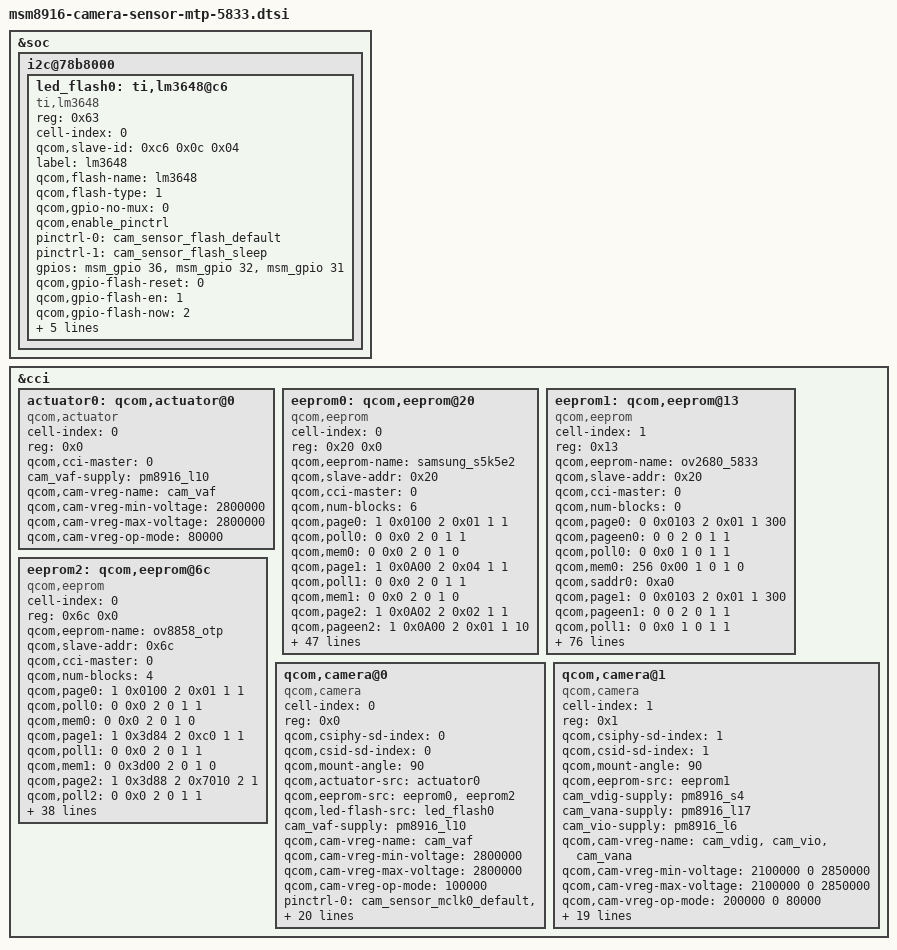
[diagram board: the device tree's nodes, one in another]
/*
 * Copyright (c) 2014-2015, The Linux Foundation. All rights reserved.
 *
 * This program is free software; you can redistribute it and/or modify
 * it under the terms of the GNU General Public License version 2 and
 * only version 2 as published by the Free Software Foundation.
 *
 * This program is distributed in the hope that it will be useful,
 * but WITHOUT ANY WARRANTY; without even the implied warranty of
 * MERCHANTABILITY or FITNESS FOR A PARTICULAR PURPOSE.  See the
 * GNU General Public License for more details.
 */

&soc {
// [5833][FlashLED][akenhsu] Porting LM3648 Flash LED for ASUS 5833 20160324 BEGIN
	i2c@78b8000 { /* BLSP1 QUP4 */
		led_flash0: ti,lm3648@c6 {
			reg = <0x63>;
			cell-index = <0>;
			qcom,slave-id = <0xc6 0x0c 0x04>;
			compatible = "ti,lm3648";
			label = "lm3648";
			qcom,flash-name = "lm3648";
			qcom,flash-type = <1>;
			qcom,gpio-no-mux = <0>;
			qcom,enable_pinctrl;
			pinctrl-names = "cam_flash_default", "cam_flash_suspend";
			pinctrl-0 = <&cam_sensor_flash_default>;
			pinctrl-1 = <&cam_sensor_flash_sleep>;
			gpios = <&msm_gpio 36 0>,
					<&msm_gpio 32 0>,
				<&msm_gpio 31 0>;
			qcom,gpio-flash-reset = <0>;
			qcom,gpio-flash-en = <1>;
			qcom,gpio-flash-now = <2>;
			qcom,gpio-req-tbl-num = <0 1 2>;
			qcom,gpio-req-tbl-flags = <0 0 0>;
			qcom,gpio-req-tbl-label = "FLASH_RST",
				"FLASH_EN",
				"FLASH_NOW";
			qcom,cci-master = <0>;
		};
	};
// [5833][FlashLED]20160324 END
};

&cci {

	actuator0: qcom,actuator@0 {
		cell-index = <0>;
		reg = <0x0>;
		compatible = "qcom,actuator";
		qcom,cci-master = <0>;
		cam_vaf-supply = <&pm8916_l10>;
		qcom,cam-vreg-name = "cam_vaf";
		qcom,cam-vreg-min-voltage = <2800000>;
		qcom,cam-vreg-max-voltage = <2800000>;
		qcom,cam-vreg-op-mode = <80000>;
	};

	eeprom0: qcom,eeprom@20 {
		cell-index = <0>;
		reg = <0x20 0x0>;
		qcom,eeprom-name = "samsung_s5k5e2";
		compatible = "qcom,eeprom";
		qcom,slave-addr = <0x20>; // S5K5E2
		qcom,cci-master = <0>;

		qcom,num-blocks = <6>;
		qcom,page0 = <1 0x0100 2 0x01 1 1>;
		qcom,poll0 = <0 0x0 2 0 1 1>;
		qcom,mem0 = <0 0x0 2 0 1 0>;
		qcom,page1 = <1 0x0A00 2 0x04 1 1>;
		qcom,poll1 = <0 0x0 2 0 1 1>;
		qcom,mem1 = <0 0x0 2 0 1 0>;
		qcom,page2 = <1 0x0A02 2 0x02 1 1>;
		qcom,pageen2 = <1 0x0A00 2 0x01 1 10>;
		qcom,poll2 = <0 0x0 2 0 1 1>;
		qcom,mem2 = <64 0x0A04 2 0 1 0>;
		qcom,page3 = <1 0x0A02 2 0x03 1 1>;
		qcom,pageen3 = <1 0x0A00 2 0x01 1 10>;
		qcom,poll3 = <0 0x0 2 0 1 1>;
		qcom,mem3 = <64 0x0A04 2 0 1 0>; 
		qcom,page4 = <1 0x0A02 2 0x0f 1 1>;
		qcom,pageen4 = <1 0x0A00 2 0x01 1 10>;
		qcom,poll4 = <0 0x0 2 0 1 1>;
		qcom,mem4 = <2 0x0A42 2 0 1 0>; 
		qcom,page5 = <1 0x0A00 2 0x04 1 1>;
		qcom,pageen5 = <1 0x0A00 2 0x00 1 10>;
		qcom,poll5 = <0 0x0 2 0 1 1>;
		qcom,mem5 = <0 0x0 2 0 1 0>;


		pinctrl-names = "cam_default", "cam_suspend";
		pinctrl-0 = <&cam_sensor_mclk0_default &cam_sensor_rear_default>;
		pinctrl-1 = <&cam_sensor_mclk0_sleep &cam_sensor_rear_sleep>;
		qcom,gpio-no-mux = <0>; //no use on the code
		gpios = <&msm_gpio 26 0>,
			<&msm_gpio 34 0>,
			<&msm_gpio 8 0>,
			<&msm_gpio 9 0>,
			<&msm_gpio 23 0>,
			<&msm_gpio 22 0>;
		qcom,gpio-reset = <1>;
		qcom,gpio-vio = <2>;
		qcom,gpio-vana = <3>;
		qcom,gpio-vdig = <4>;
		qcom,gpio-req-tbl-num = <0 1 2 3 4>;
		qcom,gpio-req-tbl-flags = <1 0 0 0 0>;
		qcom,gpio-req-tbl-label = "CAMIF_MCLK",
			"CAM_RESET1",
			"CAM_1V8_EN",
			"CAM_2V8_EN",
			"CAM_1V2_EN";
	
		//qcom,gpio-set-tbl-num = <1 1>;
		//qcom,gpio-set-tbl-flags = <0 2>;
		//qcom,gpio-set-tbl-delay = <1000 4000>;
		qcom,csi-lane-assign = <0x4320>;
		qcom,csi-lane-mask = <0x3>;
		qcom,cam-power-seq-type = "sensor_gpio", "sensor_gpio", "sensor_gpio","sensor_gpio", //init gpio to low
		 "sensor_gpio", "sensor_gpio", "sensor_gpio", "sensor_clk","sensor_gpio";
		qcom,cam-power-seq-val = "sensor_gpio_reset","sensor_gpio_vdig", "sensor_gpio_vana", "sensor_gpio_vio",
			     "sensor_gpio_vio", "sensor_gpio_vana","sensor_gpio_vdig" ,"sensor_cam_mclk","sensor_gpio_reset";
		qcom,cam-power-seq-cfg-val = <0 0 0 0  1 1 1 23880000 1>;
		qcom,cam-power-seq-delay =   <1 1 1 10 5 0 0  10      5>;
		qcom,mclk-23880000;		
		clocks = <&clock_gcc clk_mclk0_clk_src>,
				<&clock_gcc clk_gcc_camss_mclk0_clk>;
		clock-names = "cam_src_clk", "cam_clk";
	};
	eeprom1: qcom,eeprom@13 {
		cell-index = <1>;
		reg = <0x13>;
		qcom,eeprom-name = "ov2680_5833";
		compatible = "qcom,eeprom";
		qcom,slave-addr = <0x20>; // OV2680
		qcom,cci-master = <0>; // Adding
		
		qcom,num-blocks = <0>;

		qcom,page0 = <0 0x0103 2 0x01 1 300>;		
		qcom,pageen0 = <0 0 2 0 1 1>;		
		qcom,poll0 = <0 0x0 1 0 1 1>;
		qcom,mem0 = <256 0x00 1 0 1 0>;
		qcom,saddr0 = <0xa0>;

		qcom,page1 = <0 0x0103 2 0x01 1 300>;		
		qcom,pageen1 = <0 0 2 0 1 1>;
		qcom,poll1 = <0 0x0 1 0 1 1>;
		qcom,mem1 = <256 0x00 1 0 1 0>;
		qcom,saddr1 = <0xa2>;	
		
		qcom,page2 = <0 0x0103 2 0x01 1 300>;			
		qcom,pageen2 = <0 0 2 0 1 1>;
		qcom,poll2 = <0 0x0 1 0 1 1>;
		qcom,mem2 = <256 0x00 1 0 1 0>;
		qcom,saddr2 = <0xa4>;	

		qcom,page3 = <0 0x0103 2 0x01 1 300>;
		qcom,pageen3 = <0 0 2 0 1 1>;
		qcom,poll3 = <0 0x0 1 0 1 1>;
		qcom,mem3 = <256 0x00 1 0 1 0>;
		qcom,saddr3 = <0xa6>;
		
		qcom,page4 = <0 0x0103 2 0x01 1 300>;
		qcom,pageen4 = <0 0 2 0 1 1>;
		qcom,poll4 = <0 0x0 1 0 1 1>;
		qcom,mem4 = <256 0x00 1 0 1 0>;
		qcom,saddr4 = <0xa8>;
		
		qcom,page5 = <0 0x0103 2 0x01 1 300>;
		qcom,pageen5 = <0 0 2 0 1 1>;
		qcom,poll5 = <0 0x0 1 0 1 1>;
		qcom,mem5 = <256 0x00 1 0 1 0>;
		qcom,saddr5 = <0xaa>;
		
		qcom,page6 = <0 0x0103 2 0x01 1 300>;
		qcom,pageen6 = <0 0 2 0 1 1>;
		qcom,poll6 = <0 0x0 1 0 1 1>;
		qcom,mem6 = <256 0x00 1 0 1 0>;
		qcom,saddr6 = <0xac>;	
		
		qcom,page7 = <0 0x0103 2 0x01 1 300>;
		qcom,pageen7 = <0 0 2 0 1 1>;
		qcom,poll7 = <0 0x0 1 0 1 1>;
		qcom,mem7 = <256 0x00 1 0 1 0>;
		qcom,saddr7 = <0xae>;

		cam_vdig-supply = <&pm8916_s4>;
		cam_vio-supply = <&pm8916_l17>;
		cam_vana-supply = <&pm8916_l6>;
		qcom,cam-vreg-name = "cam_vdig", "cam_vio", "cam_vana";
		qcom,cam-vreg-min-voltage = <2100000 0 2850000>;
		qcom,cam-vreg-max-voltage = <2100000 0 2850000>;
		qcom,cam-vreg-op-mode = <200000 0 80000>;
		pinctrl-names = "cam_default", "cam_suspend";
		pinctrl-0 = <&cam_sensor_mclk1_default &cam_sensor_front_default>;
		pinctrl-1 = <&cam_sensor_mclk1_sleep &cam_sensor_front_sleep>;
		qcom,gpio-no-mux = <0>;
		gpios = <&msm_gpio 27 0>,
			<&msm_gpio 33 0>,
			<&msm_gpio 8 0>,
			<&msm_gpio 9 0>,
			<&msm_gpio 23 0>;
		qcom,gpio-reset = <1>;
		qcom,gpio-vio = <2>;
		qcom,gpio-vana = <3>;
		qcom,gpio-vdig = <4>;
		qcom,gpio-req-tbl-num = <0 1 2 3 4>;
		qcom,gpio-req-tbl-flags = <1 0 0 0 0>;
		qcom,gpio-req-tbl-label = "CAMIF_MCLK",
			"CAM_RESET",
			"CAM_1V8_EN",
			"CAM_2V8_EN",
			"CAM_1V2_EN";
		qcom,gpio-set-tbl-num = <1 1>;
		qcom,gpio-set-tbl-flags = <0 2>;
		qcom,gpio-set-tbl-delay = <1000 4000>;

		qcom,cam-power-seq-type = "sensor_gpio", "sensor_gpio", "sensor_gpio",
			"sensor_gpio", "sensor_gpio", "sensor_gpio",
			"sensor_gpio", "sensor_gpio", "sensor_clk", "sensor_gpio";
		qcom,cam-power-seq-val = "sensor_gpio_vio", "sensor_gpio_vana", "sensor_gpio_vdig",
			"sensor_gpio_vio", "sensor_gpio_vana", "sensor_gpio_vdig",
			"sensor_gpio_reset", "sensor_gpio_reset", "sensor_cam_mclk", "sensor_gpio_reset";
		qcom,cam-power-seq-cfg-val = <0 0 0 1 1 1 0 1 23880000 1>;
		qcom,cam-power-seq-delay = <0 0 0 1 1 1 15 10 10 10>;

		qcom,mclk-23880000;
		clocks = <&clock_gcc clk_mclk1_clk_src>,
				<&clock_gcc clk_gcc_camss_mclk1_clk>;
		clock-names = "cam_src_clk", "cam_clk";
	};	
	eeprom2: qcom,eeprom@6c {
		cell-index = <0>;
		reg = <0x6c 0x0>;
		qcom,eeprom-name = "ov8858_otp";
		compatible = "qcom,eeprom";
		qcom,slave-addr = <0x6c>; // OV8858
		qcom,cci-master = <0>;

		qcom,num-blocks = <4>;
		qcom,page0 = <1 0x0100 2 0x01 1 1>;
		qcom,poll0 = <0 0x0 2 0 1 1>;
		qcom,mem0 = <0 0x0 2 0 1 0>;
		qcom,page1 = <1 0x3d84 2 0xc0 1 1>;
		qcom,poll1 = <0 0x0 2 0 1 1>;
		qcom,mem1 = <0 0x3d00 2 0 1 0>;
		qcom,page2 = <1 0x3d88 2 0x7010 2 1>;
		qcom,poll2 = <0 0x0 2 0 1 1>;
		qcom,mem2 = <0 0x3d00 2 0 1 0>;
		qcom,page3 = <1 0x3d8A 2 0x720f 2 1>;
		qcom,pageen3 = <1 0x3d81 2 0x01 1 10>;
		qcom,poll3 = <0 0x0 2 0 1 1>;
		qcom,mem3 = <512 0x7010 2 0 1 1>;
/*
		qcom,num-blocks = <9>;
		qcom,page0 = <1 0x0103 2 0x01 1 300>;		
		qcom,pageen0 = <0 0 2 0 1 1>;		
		qcom,poll0 = <0 0x0 1 0 1 1>;		
		qcom,mem0 = <0 0x0 2 0 1 0>;		
		qcom,page1 = <1 0x0100 2 0x01 1 300>;		
		qcom,pageen1 = <1 0x5002 2 0x0 1 10>;		
		qcom,poll1 = <0 0x0 1 0 1 1>;		
		qcom,mem1 = <0 0x0 2 0 1 0>;		
		qcom,page2 = <1 0x3d84 2 0xc0 1 1>;		
		qcom,pageen2 = <0 0 2 0 1 1>;		
		qcom,poll2 = <0 0x0 1 0 1 1>;		
		qcom,mem2 = <0 0x0 2 0 1 0>;		
		qcom,page3 = <1 0x3d88 2 0x70 1 1>;		
		qcom,pageen3 = <0 0 2 0 1 1>;		
		qcom,poll3 = <0 0x0 1 0 1 1>;		
		qcom,mem3 = <0 0x0 2 0 1 0>;		
		qcom,page4 = <1 0x3d89 2 0x10 1 1>;		
		qcom,pageen4 = <0 0 2 0 1 1>;		
		qcom,poll4= <0 0x0 1 0 1 1>;		
		qcom,mem4 = <0 0x0 2 0 1 0>;		
		qcom,page5 = <1 0x3d8A 2 0x72 1 1>;		
		qcom,pageen5 = <0 0 2 0 1 1>;		
		qcom,poll5 = <0 0x0 1 0 1 1>;		
		qcom,mem5 = <0 0x0 2 0 1 0>;		
		qcom,page6 = <1 0x3d8B 2 0x10 1 1>;		
		qcom,pageen6 = <0 0 2 0 1 1>;		
		qcom,poll6 = <0 0x0 1 0 1 1>;		
		qcom,mem6 = <0 0x0 2 0 1 0>;		
		qcom,page7 = <1 0x3d81 2 0x01 1 100>;		
		qcom,pageen7 = <0 0 2 0 1 1>;		
		qcom,poll7 = <0 0x0 1 0 1 1>;		
		qcom,mem7 = <512 0x7010 2 0 1 0>;		
		qcom,page8 = <1 0x0100 2 0 1 10>;		
		qcom,pageen8 = <1 0x5002 2 8 1 10>;		
		qcom,poll8 = <0 0x0 1 0 1 1>;		
		qcom,mem8 = <0 0 2 0 1 0>;
*/

		pinctrl-names = "cam_default", "cam_suspend";
		pinctrl-0 = <&cam_sensor_mclk0_default &cam_sensor_rear_default>;
		pinctrl-1 = <&cam_sensor_mclk0_sleep &cam_sensor_rear_sleep>;
		qcom,gpio-no-mux = <0>; //no use on the code
		gpios = <&msm_gpio 26 0>,
			<&msm_gpio 34 0>,
			<&msm_gpio 8 0>,
			<&msm_gpio 9 0>,
			<&msm_gpio 23 0>,
			<&msm_gpio 22 0>;
		qcom,gpio-reset = <1>;
		qcom,gpio-vio = <2>;
		qcom,gpio-vana = <3>;
		qcom,gpio-vdig = <4>;
		qcom,gpio-req-tbl-num = <0 1 2 3 4>;
		qcom,gpio-req-tbl-flags = <1 0 0 0 0>;
		qcom,gpio-req-tbl-label = "CAMIF_MCLK",
			"CAM_RESET1",
			"CAM_1V8_EN",
			"CAM_2V8_EN",
			"CAM_1V2_EN";
	
		//qcom,gpio-set-tbl-num = <1 1>;
		//qcom,gpio-set-tbl-flags = <0 2>;
		//qcom,gpio-set-tbl-delay = <1000 4000>;
		qcom,csi-lane-assign = <0x4320>;
		qcom,csi-lane-mask = <0xf>;
		qcom,cam-power-seq-type = "sensor_gpio", "sensor_gpio", "sensor_gpio","sensor_gpio", //init gpio to low
		 "sensor_gpio", "sensor_gpio", "sensor_gpio", "sensor_clk","sensor_gpio";
		qcom,cam-power-seq-val = "sensor_gpio_reset","sensor_gpio_vdig", "sensor_gpio_vana", "sensor_gpio_vio",
			     "sensor_gpio_vio", "sensor_gpio_vana","sensor_gpio_vdig" ,"sensor_cam_mclk","sensor_gpio_reset";
		qcom,cam-power-seq-cfg-val = <0 0 0 0  1 1 1 23880000 1>;
		qcom,cam-power-seq-delay =   <1 1 1 10 5 0 0  10      5>;
		qcom,mclk-23880000;		
		clocks = <&clock_gcc clk_mclk0_clk_src>,
				<&clock_gcc clk_gcc_camss_mclk0_clk>;
		clock-names = "cam_src_clk", "cam_clk";
	};
	qcom,camera@0 {
		cell-index = <0>;
		compatible = "qcom,camera";
		reg = <0x0>;
		qcom,csiphy-sd-index = <0>;
		qcom,csid-sd-index = <0>;
		qcom,mount-angle = <90>;
		qcom,actuator-src = <&actuator0>;
		qcom,eeprom-src = <&eeprom0 &eeprom2>;
		qcom,led-flash-src = <&led_flash0>;
		//cam_vdig-supply = <&pm8916_s4>;
		//cam_vana-supply = <&pm8916_l17>;
		//cam_vio-supply = <&pm8916_l6>;
		cam_vaf-supply = <&pm8916_l10>;
		qcom,cam-vreg-name = "cam_vaf";
		qcom,cam-vreg-min-voltage = <2800000>;
		qcom,cam-vreg-max-voltage = <2800000>;
		qcom,cam-vreg-op-mode = <100000>;
		pinctrl-names = "cam_default", "cam_suspend";
		pinctrl-0 = <&cam_sensor_mclk0_default &cam_sensor_rear_default>;
		pinctrl-1 = <&cam_sensor_mclk0_sleep &cam_sensor_rear_sleep>;
		gpios = <&msm_gpio 26 0>,
			<&msm_gpio 34 0>,
			<&msm_gpio 8 0>,
			<&msm_gpio 9 0>,
			<&msm_gpio 23 0>,
			<&msm_gpio 22 0>;
		qcom,gpio-reset = <1>;
		qcom,gpio-vio = <2>;
		qcom,gpio-vana = <3>;
		qcom,gpio-vdig = <4>;
		qcom,gpio-req-tbl-num = <0 1 2 3 4>;
		qcom,gpio-req-tbl-flags = <1 0 0 0 0>;
		qcom,gpio-req-tbl-label = "CAMIF_MCLK",
			"CAM_RESET1",
			"CAM_1V8_EN",
			"CAM_2V8_EN",
			"CAM_1V2_EN";
		qcom,sensor-position = <0>;
		qcom,sensor-mode = <0>;
		qcom,cci-master = <0>;
		qcom,mclk-23880000;
		status = "ok";
		clocks = <&clock_gcc clk_mclk0_clk_src>,
				<&clock_gcc clk_gcc_camss_mclk0_clk>;
		clock-names = "cam_src_clk", "cam_clk";
	};

	qcom,camera@1 {
		cell-index = <1>;
		compatible = "qcom,camera";
		reg = <0x1>;
		qcom,csiphy-sd-index = <1>;
		qcom,csid-sd-index = <1>;
		qcom,mount-angle = <90>;
		qcom,eeprom-src = <&eeprom1>;
		cam_vdig-supply = <&pm8916_s4>;
		cam_vana-supply = <&pm8916_l17>;
		cam_vio-supply = <&pm8916_l6>;
		qcom,cam-vreg-name = "cam_vdig", "cam_vio", "cam_vana";
		qcom,cam-vreg-min-voltage = <2100000 0 2850000>;
		qcom,cam-vreg-max-voltage = <2100000 0 2850000>;
		qcom,cam-vreg-op-mode = <200000 0 80000>;
		pinctrl-names = "cam_default", "cam_suspend";
		pinctrl-0 = <&cam_sensor_mclk1_default &cam_sensor_front_default>;
		pinctrl-1 = <&cam_sensor_mclk1_sleep &cam_sensor_front_sleep>;
		gpios = <&msm_gpio 27 0>,
			<&msm_gpio 33 0>,
			<&msm_gpio 8 0>,
			<&msm_gpio 9 0>,
			<&msm_gpio 23 0>;
		qcom,gpio-reset = <1>;
		qcom,gpio-vio = <2>;
		qcom,gpio-vana = <3>;
		qcom,gpio-vdig = <4>;
		qcom,gpio-req-tbl-num = <0 1 2 3 4>;
		qcom,gpio-req-tbl-flags = <1 0 0 0 0>;
		qcom,gpio-req-tbl-label = "CAMIF_MCLK",
			"CAM_RESET",
			"CAM_1V8_EN",
			"CAM_2V8_EN",
			"CAM_1V2_EN";
		qcom,cci-master = <0>;
		qcom,mclk-23880000;
		status = "ok";
		clocks = <&clock_gcc clk_mclk1_clk_src>,
				<&clock_gcc clk_gcc_camss_mclk1_clk>;
		clock-names = "cam_src_clk", "cam_clk";
	};
};
